AUTOSAR XML (schema 4-2-2)
package /System
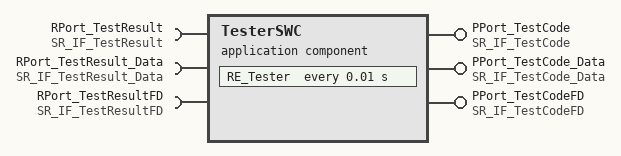
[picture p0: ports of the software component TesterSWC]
  application sw component type TesterSWC
    provide port PPort_TestCode: provided-interface=SR_IF_TestCode
    require port RPort_TestResult: required-interface=SR_IF_TestResult
    provide port PPort_TestCode_Data: provided-interface=SR_IF_TestCode_Data
    require port RPort_TestResult_Data: required-interface=SR_IF_TestResult_Data
    provide port PPort_TestCodeFD: provided-interface=SR_IF_TestCodeFD
    require port RPort_TestResultFD: required-interface=SR_IF_TestResultFD
    behavior InternalBehavior: data-type-mapping=DataTypeMappingSet_ASW
      timing event TE_10ms: start-on-event=RE_Tester, period=0.01
      runnable RE_Tester
        data-receive-point-by-arguments:
          access DRATestResult: accessed-variable=RPort_TestResult.TestResult
          access DRPA_TestResult_Data_0: accessed-variable=RPort_TestResult_Data.TestResult_Data
        data-send-points:
          access DWATestCode: accessed-variable=PPort_TestCode.TestCode
          access DSP_TestCode_Data_0: accessed-variable=PPort_TestCode_Data.TestCode_Data
